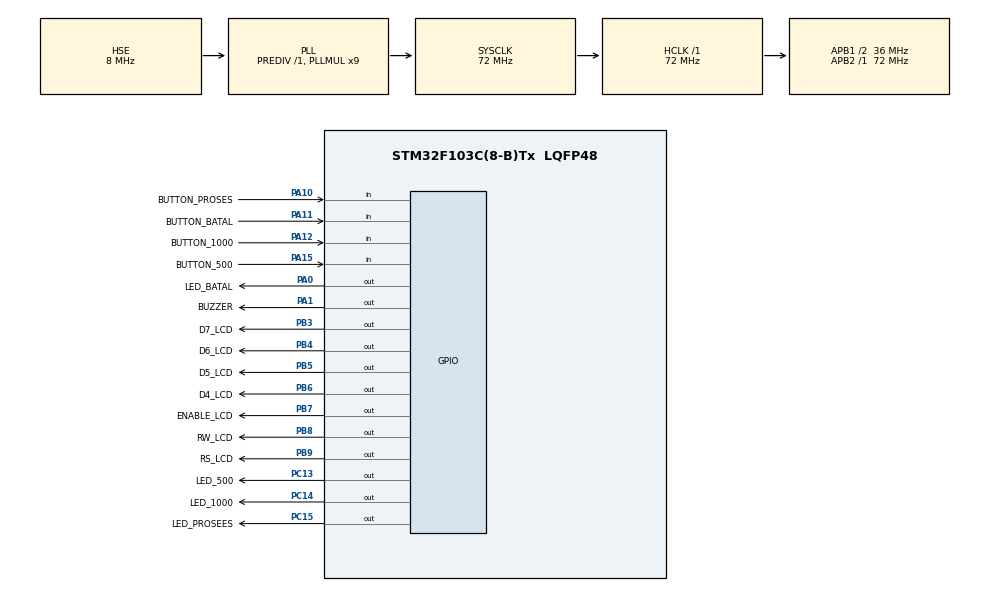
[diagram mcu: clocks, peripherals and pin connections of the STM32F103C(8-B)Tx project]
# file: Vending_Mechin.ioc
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Mcu.Family=STM32F1
Mcu.Name=STM32F103C(8-B)Tx
Mcu.Package=LQFP48
NVIC.PriorityGroup=NVIC_PRIORITYGROUP_4
PA0-WKUP.GPIO_Label=LED_BATAL
PA0-WKUP.Signal=GPIO_Output
PA1.GPIO_Label=BUZZER
PA1.Signal=GPIO_Output
PA10.GPIO_Label=BUTTON_PROSES
PA10.GPIO_PuPd=GPIO_PULLUP
PA10.Signal=GPIO_Input
PA11.GPIO_Label=BUTTON_BATAL
PA11.GPIO_PuPd=GPIO_PULLUP
PA11.Signal=GPIO_Input
PA12.GPIO_Label=BUTTON_1000
PA12.GPIO_PuPd=GPIO_PULLUP
PA12.Signal=GPIO_Input
PA13.Mode=Serial_Wire
PA13.Signal=SYS_JTMS-SWDIO
PA14.Mode=Serial_Wire
PA14.Signal=SYS_JTCK-SWCLK
PA15.GPIO_Label=BUTTON_500
PA15.GPIO_PuPd=GPIO_PULLUP
PA15.Signal=GPIO_Input
PB3.GPIO_Label=D7_LCD
PB3.Signal=GPIO_Output
PB4.GPIO_Label=D6_LCD
PB4.Signal=GPIO_Output
PB5.GPIO_Label=D5_LCD
PB5.Signal=GPIO_Output
PB6.GPIO_Label=D4_LCD
PB6.Signal=GPIO_Output
PB7.GPIO_Label=ENABLE_LCD
PB7.Signal=GPIO_Output
PB8.GPIO_Label=RW_LCD
PB8.Signal=GPIO_Output
PB9.GPIO_Label=RS_LCD
PB9.Signal=GPIO_Output
PC13-TAMPER-RTC.GPIO_Label=LED_500
PC13-TAMPER-RTC.Signal=GPIO_Output
PC14-OSC32_IN.GPIO_Label=LED_1000
PC14-OSC32_IN.Signal=GPIO_Output
PC15-OSC32_OUT.GPIO_Label=LED_PROSEES
PC15-OSC32_OUT.Signal=GPIO_Output
PD0-OSC_IN.Mode=HSE-External-Oscillator
PD0-OSC_IN.Signal=RCC_OSC_IN
PD1-OSC_OUT.Mode=HSE-External-Oscillator
PD1-OSC_OUT.Signal=RCC_OSC_OUT
ProjectManager.HeapSize=0x200
ProjectManager.StackSize=0x400
ProjectManager.TargetToolchain=STM32CubeIDE
RCC.AHBFreq_Value=72000000
RCC.APB1CLKDivider=RCC_HCLK_DIV2
RCC.APB1Freq_Value=36000000
RCC.APB1TimFreq_Value=72000000
RCC.APB2Freq_Value=72000000
RCC.APB2TimFreq_Value=72000000
RCC.HCLKFreq_Value=72000000
RCC.PLLMUL=RCC_PLL_MUL9
RCC.PLLSourceVirtual=RCC_PLLSOURCE_HSE
RCC.SYSCLKFreq_VALUE=72000000
RCC.SYSCLKSource=RCC_SYSCLKSOURCE_PLLCLK
RCC.USBFreq_Value=72000000
TIM2.Prescaler=35999
VP_TIM2_VS_ClockSourceITR.Mode=TriggerSource_ITR0
VP_TIM2_VS_ControllerModeClock.Mode=Clock Mode
board=custom

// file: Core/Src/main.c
/* USER CODE BEGIN Header */
/**
  ******************************************************************************
  * @file           : main.c
  * @brief          : Main program body
  ******************************************************************************
  * @attention
  *
  * <h2><center>&copy; Copyright (c) 2019 STMicroelectronics.
  * All rights reserved.</center></h2>
  *
  * This software component is licensed by ST under BSD 3-Clause license,
  * the "License"; You may not use this file except in compliance with the
  * License. You may obtain a copy of the License at:
  *                        opensource.org/licenses/BSD-3-Clause
  *
  ******************************************************************************
  */
/* USER CODE END Header */

#include "main.h"

/* USER CODE BEGIN Includes */
#include "LCD.h"
#include "Task.h"
/* USER CODE END Includes */

TIM_HandleTypeDef htim2;

void SystemClock_Config(void);
static void MX_GPIO_Init(void);
static void MX_TIM2_Init(void);

int main(void)
{

  /* MCU Configuration--------------------------------------------------------*/

  /* Reset of all peripherals, Initializes the Flash interface and the Systick. */
  HAL_Init();

  /* Configure the system clock */
  SystemClock_Config();

  /* Initialize all configured peripherals */
  MX_GPIO_Init();
  MX_TIM2_Init();
  /* USER CODE BEGIN 2 */
  LCD_Init();
  HAL_Delay(10);
  task_init();
  HAL_TIM_Base_Start_IT(&htim2);
  /* USER CODE END 2 */

  /* Infinite loop */
  while (1)
  {

  }
}

void SystemClock_Config(void)
{
  RCC_OscInitTypeDef RCC_OscInitStruct = {0};
  RCC_ClkInitTypeDef RCC_ClkInitStruct = {0};

  /** Initializes the CPU, AHB and APB busses clocks
  */
  RCC_OscInitStruct.OscillatorType = RCC_OSCILLATORTYPE_HSE;
  RCC_OscInitStruct.HSEState = RCC_HSE_ON;
  RCC_OscInitStruct.HSEPredivValue = RCC_HSE_PREDIV_DIV1;
  RCC_OscInitStruct.HSIState = RCC_HSI_ON;
  RCC_OscInitStruct.PLL.PLLState = RCC_PLL_ON;
  RCC_OscInitStruct.PLL.PLLSource = RCC_PLLSOURCE_HSE;
  RCC_OscInitStruct.PLL.PLLMUL = RCC_PLL_MUL9;
  if (HAL_RCC_OscConfig(&RCC_OscInitStruct) != HAL_OK)
  {
    Error_Handler();
  }
  /** Initializes the CPU, AHB and APB busses clocks
  */
  RCC_ClkInitStruct.ClockType = RCC_CLOCKTYPE_HCLK|RCC_CLOCKTYPE_SYSCLK
                              |RCC_CLOCKTYPE_PCLK1|RCC_CLOCKTYPE_PCLK2;
  RCC_ClkInitStruct.SYSCLKSource = RCC_SYSCLKSOURCE_PLLCLK;
  RCC_ClkInitStruct.AHBCLKDivider = RCC_SYSCLK_DIV1;
  RCC_ClkInitStruct.APB1CLKDivider = RCC_HCLK_DIV2;
  RCC_ClkInitStruct.APB2CLKDivider = RCC_HCLK_DIV1;

  if (HAL_RCC_ClockConfig(&RCC_ClkInitStruct, FLASH_LATENCY_2) != HAL_OK)
  {
    Error_Handler();
  }
}

static void MX_TIM2_Init(void)
{

  TIM_SlaveConfigTypeDef sSlaveConfig = {0};
  TIM_MasterConfigTypeDef sMasterConfig = {0};

  htim2.Instance = TIM2;
  htim2.Init.Prescaler = 35999;
  htim2.Init.CounterMode = TIM_COUNTERMODE_UP;
  htim2.Init.Period = 0;
  htim2.Init.ClockDivision = TIM_CLOCKDIVISION_DIV1;
  htim2.Init.AutoReloadPreload = TIM_AUTORELOAD_PRELOAD_DISABLE;
  if (HAL_TIM_Base_Init(&htim2) != HAL_OK)
  {
    Error_Handler();
  }
  sSlaveConfig.SlaveMode = TIM_SLAVEMODE_EXTERNAL1;
  sSlaveConfig.InputTrigger = TIM_TS_ITR0;
  if (HAL_TIM_SlaveConfigSynchro(&htim2, &sSlaveConfig) != HAL_OK)
  {
    Error_Handler();
  }
  sMasterConfig.MasterOutputTrigger = TIM_TRGO_RESET;
  sMasterConfig.MasterSlaveMode = TIM_MASTERSLAVEMODE_DISABLE;
  if (HAL_TIMEx_MasterConfigSynchronization(&htim2, &sMasterConfig) != HAL_OK)
  {
    Error_Handler();
  }

}

static void MX_GPIO_Init(void)
{
  GPIO_InitTypeDef GPIO_InitStruct = {0};

  /* GPIO Ports Clock Enable */
  __HAL_RCC_GPIOC_CLK_ENABLE();
  __HAL_RCC_GPIOD_CLK_ENABLE();
  __HAL_RCC_GPIOA_CLK_ENABLE();
  __HAL_RCC_GPIOB_CLK_ENABLE();

  /*Configure GPIO pin Output Level */
  HAL_GPIO_WritePin(GPIOC, LED_500_Pin|LED_1000_Pin|LED_PROSEES_Pin, GPIO_PIN_RESET);

  /*Configure GPIO pin Output Level */
  HAL_GPIO_WritePin(GPIOA, LED_BATAL_Pin|BUZZER_Pin, GPIO_PIN_RESET);

  /*Configure GPIO pin Output Level */
  HAL_GPIO_WritePin(GPIOB, D7_LCD_Pin|D6_LCD_Pin|D5_LCD_Pin|D4_LCD_Pin
                          |ENABLE_LCD_Pin|RW_LCD_Pin|RS_LCD_Pin, GPIO_PIN_RESET);

  /*Configure GPIO pins : LED_500_Pin LED_1000_Pin LED_PROSEES_Pin */
  GPIO_InitStruct.Pin = LED_500_Pin|LED_1000_Pin|LED_PROSEES_Pin;
  GPIO_InitStruct.Mode = GPIO_MODE_OUTPUT_PP;
  GPIO_InitStruct.Pull = GPIO_NOPULL;
  GPIO_InitStruct.Speed = GPIO_SPEED_FREQ_LOW;
  HAL_GPIO_Init(GPIOC, &GPIO_InitStruct);

  /*Configure GPIO pins : LED_BATAL_Pin BUZZER_Pin */
  GPIO_InitStruct.Pin = LED_BATAL_Pin|BUZZER_Pin;
  GPIO_InitStruct.Mode = GPIO_MODE_OUTPUT_PP;
  GPIO_InitStruct.Pull = GPIO_NOPULL;
  GPIO_InitStruct.Speed = GPIO_SPEED_FREQ_LOW;
  HAL_GPIO_Init(GPIOA, &GPIO_InitStruct);

  /*Configure GPIO pins : BUTTON_PROSES_Pin BUTTON_BATAL_Pin BUTTON_1000_Pin BUTTON_500_Pin */
  GPIO_InitStruct.Pin = BUTTON_PROSES_Pin|BUTTON_BATAL_Pin|BUTTON_1000_Pin|BUTTON_500_Pin;
  GPIO_InitStruct.Mode = GPIO_MODE_INPUT;
  GPIO_InitStruct.Pull = GPIO_PULLUP;
  HAL_GPIO_Init(GPIOA, &GPIO_InitStruct);

  /*Configure GPIO pins : D7_LCD_Pin D6_LCD_Pin D5_LCD_Pin D4_LCD_Pin
                           ENABLE_LCD_Pin RW_LCD_Pin RS_LCD_Pin */
  GPIO_InitStruct.Pin = D7_LCD_Pin|D6_LCD_Pin|D5_LCD_Pin|D4_LCD_Pin
                          |ENABLE_LCD_Pin|RW_LCD_Pin|RS_LCD_Pin;
  GPIO_InitStruct.Mode = GPIO_MODE_OUTPUT_PP;
  GPIO_InitStruct.Pull = GPIO_NOPULL;
  GPIO_InitStruct.Speed = GPIO_SPEED_FREQ_LOW;
  HAL_GPIO_Init(GPIOB, &GPIO_InitStruct);

}

void Error_Handler(void)
{
}

/************************ (C) COPYRIGHT STMicroelectronics *****END OF FILE****/
